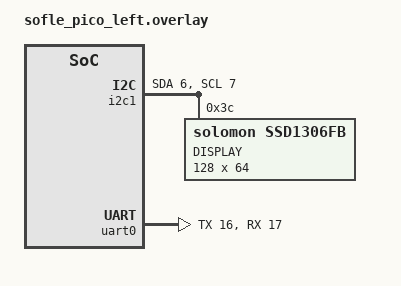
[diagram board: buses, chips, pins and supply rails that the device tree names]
#include "sofle_pico.dtsi"

&i2c1 {
    status = "okay";
    sda-pin = <6>;   // GP6
    scl-pin = <7>;   // GP7

    oled: ssd1306@3c {
        compatible = "solomon,ssd1306fb";
        reg = <0x3c>;
        label = "DISPLAY";
        width = <128>;
        height = <64>;
    };
};

&uart0 {
    status = "okay";
    tx-pin = <16>;   // GP16
    rx-pin = <17>;   // GP17
};
